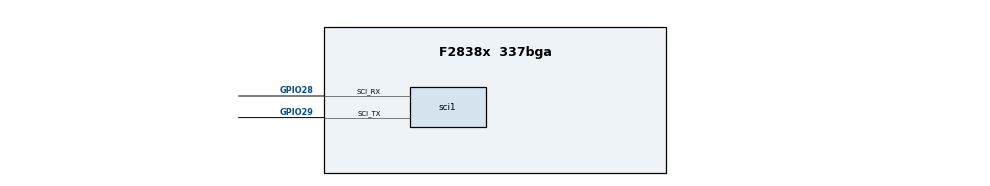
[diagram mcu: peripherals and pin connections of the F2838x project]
/**
 * @cliArgs --device "F2838x" --part "F2838x_337bga" --package "337bga" --context "CPU1" --product "C2000WARE@5.04.00.00"
 * @versions {"tool":"1.24.0+4110"}
 */

/**
 * Import the modules used in this configuration.
 */
const sci  = scripting.addModule("/driverlib/sci.js", {}, false);
const sci1 = sci.addInstance();

/**
 * Write custom configuration values to the imported modules.
 */
sci1.$name                 = "mySCI0";
sci1.sci.sci_rxPin.$assign = "GPIO28";
sci1.sci.sci_txPin.$assign = "GPIO29";
sci1.rxQual.$name          = "myGPIOQUAL0";
sci1.txQual.$name          = "myGPIOQUAL1";

/**
 * Pinmux solution for unlocked pins/peripherals. This ensures that minor changes to the automatic solver in a future
 * version of the tool will not impact the pinmux you originally saw.  These lines can be completely deleted in order to
 * re-solve from scratch.
 */
sci1.sci.$suggestSolution = "SCIA";
